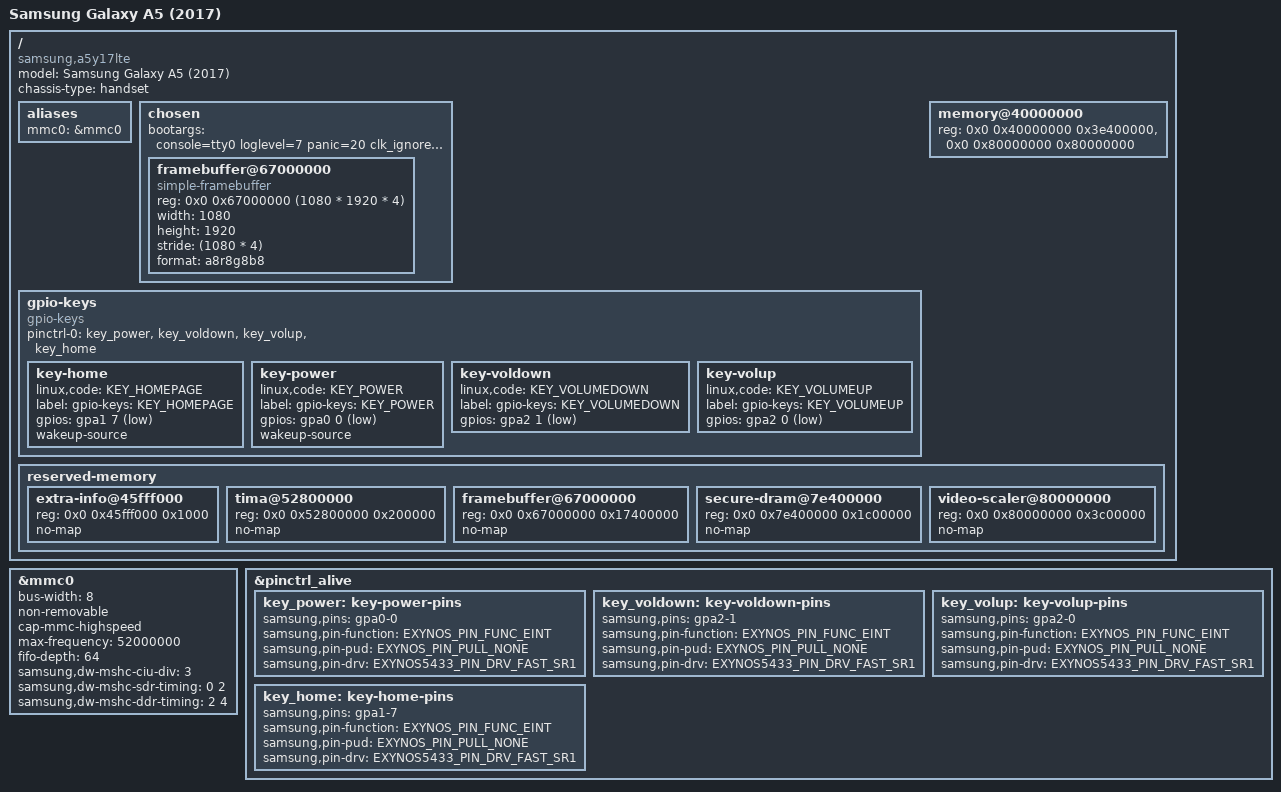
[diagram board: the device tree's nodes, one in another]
// SPDX-License-Identifier: GPL-2.0
/*
 * Samsung Galaxy A5 (2017), SM-A520F - milestone 3 (console, keys, eMMC)
 *
 *  [D] Samsung universal7880 kernel: exynos7880-a5y17lte_common.dtsi,
 *      exynos7880-rmem.dtsi
 *  [H] a5y17lte hardware readings, EVIDENCE.md section 12
 */

/dts-v1/;
#include "exynos7880.dtsi"
#include <dt-bindings/gpio/gpio.h>
#include <dt-bindings/input/input.h>

/ {
	model = "Samsung Galaxy A5 (2017)";
	compatible = "samsung,a5y17lte", "samsung,exynos7880";
	chassis-type = "handset";

	aliases {
		mmc0 = &mmc0;
	};

	chosen {
		#address-cells = <2>;
		#size-cells = <1>;
		ranges;

		bootargs = "console=tty0 loglevel=7 panic=20 clk_ignore_unused pd_ignore_unused fbcon=font:TER16x32";

		/* [H] 0x67000000, 1080x1920, ARGB8888 (R G B W bars confirmed) */
		framebuffer@67000000 {
			compatible = "simple-framebuffer";
			reg = <0x0 0x67000000 (1080 * 1920 * 4)>;
			width = <1080>;
			height = <1920>;
			stride = <(1080 * 4)>;
			format = "a8r8g8b8";
		};
	};

	/*
	 * [D] exynos7880-a5y17lte_common.dtsi gpio_keys: power gpa0-0 (116),
	 * volume down gpa2-1 (114), volume up gpa2-0 (115), home gpa1-7 (172);
	 * identical to mainline exynos7870-j5y17lte.dts.
	 */
	gpio-keys {
		compatible = "gpio-keys";
		pinctrl-names = "default";
		pinctrl-0 = <&key_power &key_voldown &key_volup &key_home>;

		key-home {
			linux,code = <KEY_HOMEPAGE>;
			label = "gpio-keys: KEY_HOMEPAGE";
			gpios = <&gpa1 7 GPIO_ACTIVE_LOW>;
			wakeup-source;
		};

		key-power {
			linux,code = <KEY_POWER>;
			label = "gpio-keys: KEY_POWER";
			gpios = <&gpa0 0 GPIO_ACTIVE_LOW>;
			wakeup-source;
		};

		key-voldown {
			linux,code = <KEY_VOLUMEDOWN>;
			label = "gpio-keys: KEY_VOLUMEDOWN";
			gpios = <&gpa2 1 GPIO_ACTIVE_LOW>;
		};

		key-volup {
			linux,code = <KEY_VOLUMEUP>;
			label = "gpio-keys: KEY_VOLUMEUP";
			gpios = <&gpa2 0 GPIO_ACTIVE_LOW>;
		};
	};

	/* [D] memory@40000000 0x3E400000 and memory@80000000 0x80000000 (3 GB) */
	memory@40000000 {
		device_type = "memory";
		reg = <0x0 0x40000000 0x3e400000>,
		      <0x0 0x80000000 0x80000000>;
	};

	/*
	 * Milestone 1 is conservative: every Samsung carve-out is no-map, so
	 * Linux never touches memory that firmware, modem or the secure world
	 * may own. [D] rmem: 0x7E400000-0x80000000 is secure DRAM and is
	 * already outside the memory node above.
	 */
	reserved-memory {
		#address-cells = <2>;
		#size-cells = <1>;
		ranges;

		/* [D] extra_info */
		extra-info@45fff000 {
			reg = <0x0 0x45fff000 0x1000>;
			no-map;
		};

		/* [D] tima_region (Samsung TIMA) */
		tima@52800000 {
			reg = <0x0 0x52800000 0x200000>;
			no-map;
		};

		/* [H] boot framebuffer, then [D] dram_init 0x67FFF000, modem_if
		 * 0x68000000, gnss_if 0x70000000, /memreserve/ 0x70400000,
		 * gpu_crc, gpu_buffer, crypto, video_nfw/fw/stream/frame up to
		 * 0x7C800000; whole range kept out until it is understood */
		framebuffer@67000000 {
			reg = <0x0 0x67000000 0x17400000>;
			no-map;
		};

		/*
		 * [D] rmem.dtsi: "0x7E400000 ~ 0x80000000 is used for secure DRAM".
		 * Outside the memory node above, but U-Boot (board/samsung/common
		 * dram_init_banksize) reports 0x40000000-0x100000000 as contiguous
		 * banks and rewrites /memory on boot, so keep it out explicitly.
		 */
		secure-dram@7e400000 {
			reg = <0x0 0x7e400000 0x1c00000>;
			no-map;
		};

		/* [D] video_scaler (secure ION) */
		video-scaler@80000000 {
			reg = <0x0 0x80000000 0x3c00000>;
			no-map;
		};
	};
};

/*
 * eMMC. [D] exynos7880-a5y17lte_common.dtsi dwmmc0: 8-bit, non-removable,
 * fifo-depth 0x40, ciu-div 3, sdr-timing <3 0 2 0>, ddr-timing <3 0 4 2>.
 * Samsung cells are <div fine-drive drive sample>; mainline takes
 * <sample drive>, so SDR <0 2>, DDR <2 4> (the same conversion of Samsung's
 * 7870 values gives mainline exynos7870-j5y17lte's <0 4>/<2 4>).
 * Milestone 3 is conservative: high-speed SDR at 52 MHz max, no DDR/HS200/
 * HS400 (those need tuning and the 1.8 V I/O regulator), no pinctrl or
 * regulators (S-Boot leaves pins and supplies configured and on).
 */
&mmc0 {
	bus-width = <8>;
	non-removable;
	cap-mmc-highspeed;
	max-frequency = <52000000>;
	fifo-depth = <64>;
	samsung,dw-mshc-ciu-div = <3>;
	samsung,dw-mshc-sdr-timing = <0 2>;
	samsung,dw-mshc-ddr-timing = <2 4>;
	status = "okay";
};

/* [D] key-power/voldown/volup/home: function 0xf (EINT), pud 0, drv 0 */
&pinctrl_alive {
	key_power: key-power-pins {
		samsung,pins = "gpa0-0";
		samsung,pin-function = <EXYNOS_PIN_FUNC_EINT>;
		samsung,pin-pud = <EXYNOS_PIN_PULL_NONE>;
		samsung,pin-drv = <EXYNOS5433_PIN_DRV_FAST_SR1>;
	};

	key_voldown: key-voldown-pins {
		samsung,pins = "gpa2-1";
		samsung,pin-function = <EXYNOS_PIN_FUNC_EINT>;
		samsung,pin-pud = <EXYNOS_PIN_PULL_NONE>;
		samsung,pin-drv = <EXYNOS5433_PIN_DRV_FAST_SR1>;
	};

	key_volup: key-volup-pins {
		samsung,pins = "gpa2-0";
		samsung,pin-function = <EXYNOS_PIN_FUNC_EINT>;
		samsung,pin-pud = <EXYNOS_PIN_PULL_NONE>;
		samsung,pin-drv = <EXYNOS5433_PIN_DRV_FAST_SR1>;
	};

	key_home: key-home-pins {
		samsung,pins = "gpa1-7";
		samsung,pin-function = <EXYNOS_PIN_FUNC_EINT>;
		samsung,pin-pud = <EXYNOS_PIN_PULL_NONE>;
		samsung,pin-drv = <EXYNOS5433_PIN_DRV_FAST_SR1>;
	};
};
